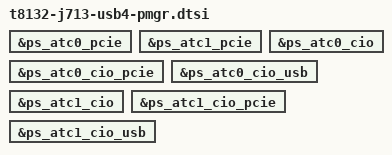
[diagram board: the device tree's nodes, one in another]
// SPDX-License-Identifier: GPL-2.0+ OR MIT
/* ACIO is the consumer that owns these domains while a cable is up. */
&ps_atc0_pcie {
	status = "okay";
};

&ps_atc1_pcie {
	status = "okay";
};

&ps_atc0_cio {
	status = "okay";
};

&ps_atc0_cio_pcie {
	status = "okay";
};

&ps_atc0_cio_usb {
	status = "okay";
};

&ps_atc1_cio {
	status = "okay";
};

&ps_atc1_cio_pcie {
	status = "okay";
};

&ps_atc1_cio_usb {
	status = "okay";
};

